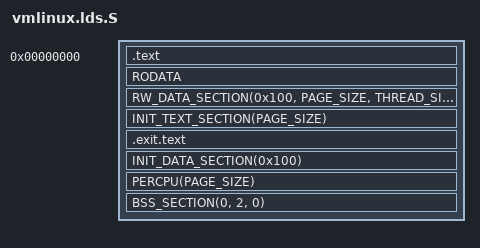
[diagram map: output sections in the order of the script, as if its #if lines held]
/* Copyright Statement:
 *
 * This software/firmware and related documentation ("MediaTek Software") are
 * protected under relevant copyright laws. The information contained herein
 * is confidential and proprietary to MediaTek Inc. and/or its licensors.
 * Without the prior written permission of MediaTek inc. and/or its licensors,
 * any reproduction, modification, use or disclosure of MediaTek Software,
 * and information contained herein, in whole or in part, shall be strictly prohibited.
 *
 * MediaTek Inc. (C) 2010. All rights reserved.
 *
 * BY OPENING THIS FILE, RECEIVER HEREBY UNEQUIVOCALLY ACKNOWLEDGES AND AGREES
 * THAT THE SOFTWARE/FIRMWARE AND ITS DOCUMENTATIONS ("MEDIATEK SOFTWARE")
 * RECEIVED FROM MEDIATEK AND/OR ITS REPRESENTATIVES ARE PROVIDED TO RECEIVER ON
 * AN "AS-IS" BASIS ONLY. MEDIATEK EXPRESSLY DISCLAIMS ANY AND ALL WARRANTIES,
 * EXPRESS OR IMPLIED, INCLUDING BUT NOT LIMITED TO THE IMPLIED WARRANTIES OF
 * MERCHANTABILITY, FITNESS FOR A PARTICULAR PURPOSE OR NONINFRINGEMENT.
 * NEITHER DOES MEDIATEK PROVIDE ANY WARRANTY WHATSOEVER WITH RESPECT TO THE
 * SOFTWARE OF ANY THIRD PARTY WHICH MAY BE USED BY, INCORPORATED IN, OR
 * SUPPLIED WITH THE MEDIATEK SOFTWARE, AND RECEIVER AGREES TO LOOK ONLY TO SUCH
 * THIRD PARTY FOR ANY WARRANTY CLAIM RELATING THERETO. RECEIVER EXPRESSLY ACKNOWLEDGES
 * THAT IT IS RECEIVER'S SOLE RESPONSIBILITY TO OBTAIN FROM ANY THIRD PARTY ALL PROPER LICENSES
 * CONTAINED IN MEDIATEK SOFTWARE. MEDIATEK SHALL ALSO NOT BE RESPONSIBLE FOR ANY MEDIATEK
 * SOFTWARE RELEASES MADE TO RECEIVER'S SPECIFICATION OR TO CONFORM TO A PARTICULAR
 * STANDARD OR OPEN FORUM. RECEIVER'S SOLE AND EXCLUSIVE REMEDY AND MEDIATEK'S ENTIRE AND
 * CUMULATIVE LIABILITY WITH RESPECT TO THE MEDIATEK SOFTWARE RELEASED HEREUNDER WILL BE,
 * AT MEDIATEK'S OPTION, TO REVISE OR REPLACE THE MEDIATEK SOFTWARE AT ISSUE,
 * OR REFUND ANY SOFTWARE LICENSE FEES OR SERVICE CHARGE PAID BY RECEIVER TO
 * MEDIATEK FOR SUCH MEDIATEK SOFTWARE AT ISSUE.
 */

/* ld script to make s390 Linux kernel
 * Written by Martin Schwidefsky (schwidefsky@de.ibm.com)
 */

#include <asm/thread_info.h>
#include <asm/page.h>
#include <asm-generic/vmlinux.lds.h>

#ifndef CONFIG_64BIT
OUTPUT_FORMAT("elf32-s390", "elf32-s390", "elf32-s390")
OUTPUT_ARCH(s390)
ENTRY(_start)
jiffies = jiffies_64 + 4;
#else
OUTPUT_FORMAT("elf64-s390", "elf64-s390", "elf64-s390")
OUTPUT_ARCH(s390:64-bit)
ENTRY(_start)
jiffies = jiffies_64;
#endif

PHDRS {
	text PT_LOAD FLAGS(5);	/* R_E */
	data PT_LOAD FLAGS(7);	/* RWE */
	note PT_NOTE FLAGS(0);	/* ___ */
}

SECTIONS
{
	. = 0x00000000;
	.text : {
	_text = .;		/* Text and read-only data */
		HEAD_TEXT
		TEXT_TEXT
		SCHED_TEXT
		LOCK_TEXT
		KPROBES_TEXT
		IRQENTRY_TEXT
		*(.fixup)
		*(.gnu.warning)
	} :text = 0x0700

	_etext = .;		/* End of text section */

	NOTES :text :note

	RODATA

#ifdef CONFIG_SHARED_KERNEL
	. = ALIGN(0x100000);	/* VM shared segments are 1MB aligned */
#endif

	. = ALIGN(PAGE_SIZE);
	_eshared = .;		/* End of shareable data */
	_sdata = .;		/* Start of data section */

	EXCEPTION_TABLE(16) :data

	RW_DATA_SECTION(0x100, PAGE_SIZE, THREAD_SIZE)

	_edata = .;		/* End of data section */

	/* will be freed after init */
	. = ALIGN(PAGE_SIZE);	/* Init code and data */
	__init_begin = .;

	INIT_TEXT_SECTION(PAGE_SIZE)

	/*
	 * .exit.text is discarded at runtime, not link time,
	 * to deal with references from __bug_table
	*/
	.exit.text : {
		EXIT_TEXT
	}

	/* early.c uses stsi, which requires page aligned data. */
	. = ALIGN(PAGE_SIZE);
	INIT_DATA_SECTION(0x100)

	PERCPU(PAGE_SIZE)
	. = ALIGN(PAGE_SIZE);
	__init_end = .;		/* freed after init ends here */

	BSS_SECTION(0, 2, 0)

	_end = . ;

	/* Debugging sections.	*/
	STABS_DEBUG
	DWARF_DEBUG

	/* Sections to be discarded */
	DISCARDS
}
